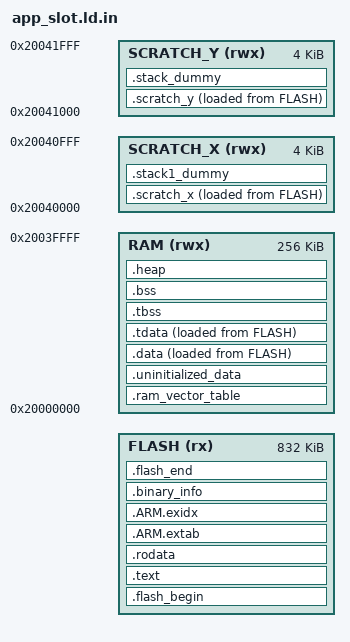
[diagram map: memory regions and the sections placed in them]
/* app_slot.ld.in -- linker script TEMPLATE for a SaftyFW application image
 * meant to run from one of the bootloader's flash slots (docs/BOOTLOADER.md
 * section 2), not from the stock pico-sdk application address.
 *
 * Derived from the vendored pico-sdk's own default app linker script:
 *   $PICO_SDK_PATH/src/rp2_common/pico_crt0/rp2040/memmap_default.ld
 * (pico-sdk 2.x, RP2040 variant -- confirmed present on this machine at
 * C:\pico-tools\pico-sdk). Read that file in full before touching this one;
 * this is a deliberate, commented divergence from it, not an independent
 * design. Everything below that is not called out in a comment is copied
 * from that file unchanged.
 *
 * Two differences from the stock script:
 *
 *   1. No `.boot2` output section, and `.boot2` input sections are
 *      explicitly discarded (see the /DISCARD/ block below). There is
 *      exactly one boot2 in the whole 2MB image -- part of the bootloader's
 *      own build, at flash offset 0 -- and it runs the ROM->boot2->
 *      bootloader handoff once, at power-on. This slot image is entered
 *      directly by the bootloader's jump_to_app() (bootloader/main.c): a
 *      `msr msp` + `bx` straight into this image's own vector table, never
 *      through boot2 again. A second boot2 copy here would be dead weight
 *      (256B) at best; worse, if left as an *unhandled orphan section*
 *      rather than explicitly discarded, GNU ld's orphan-section placement
 *      could tuck it in front of `.vectors` and silently shift the vector
 *      table off the slot's start address, which is exactly the thing
 *      jump_to_app() requires to be there. Discarding it explicitly removes
 *      that hazard rather than hoping the linker's default placement never
 *      changes.
 *
 *      (Why boot2 is a link input here at all, even though we don't want
 *      it: pico-sdk's `pico_standard_link` INTERFACE target links the
 *      `bs2_default_library` into any executable that isn't a `no_flash`
 *      binary type -- see pico_standard_link/CMakeLists.txt -- so it's
 *      present in every ordinary flash-targeted app's link inputs whether
 *      or not the app's own linker script has anywhere to put it.)
 *
 *   2. `FLASH`'s ORIGIN is a build-time placeholder,
 *      `@SAFTYFW_APP_FLASH_ORIGIN@`, substituted by CMake's configure_file()
 *      once per slot (firmware/SaftyFW/CMakeLists.txt's
 *      saftyfw_add_slot_executable() function) -- 0x10011000 for slot A,
 *      0x100E1000 for slot B. `FLASH`'s LENGTH is the hardcoded literal
 *      0xD0000 (832K == BOOTLOADER_SLOT_FLASH_SIZE), NOT computed from
 *      anything -- a linker script cannot #include a C header, so this
 *      value cannot be derived from bootloader/flash_layout.h at build
 *      time. It is a plain copy of that file's
 *      `BOOTLOADER_SLOT_FLASH_SIZE` macro, current as of 2026-08-17.
 *
 *      *** MANUAL SYNC HAZARD ***
 *      If BOOTLOADER_SLOT_FLASH_SIZE ever changes in flash_layout.h, this
 *      LENGTH must be changed here in the same commit, by hand -- nothing
 *      enforces that today. Same for the two ORIGIN values passed in from
 *      CMakeLists.txt (SAFTYFW_APP_SLOT_A_FLASH_ORIGIN /
 *      _B_FLASH_ORIGIN there), which are hand-copied from
 *      BOOTLOADER_SLOT_A_FLASH_OFFSET / _B_FLASH_OFFSET + XIP_BASE. A CI
 *      check that parses flash_layout.h's macros and asserts they match
 *      this file and CMakeLists.txt's literals would close this gap; no
 *      such check exists yet (flagged, not built, this pass).
 *
 * RAM/SCRATCH_X/SCRATCH_Y regions are byte-for-byte identical to the stock
 * script -- SRAM layout does not depend on which flash slot the code runs
 * from.
 */

MEMORY
{
    /* ORIGIN substituted per-slot by configure_file(); LENGTH is
     * BOOTLOADER_SLOT_FLASH_SIZE from bootloader/flash_layout.h, hand-synced
     * (see the MANUAL SYNC HAZARD note above). */
    FLASH(rx) : ORIGIN = @SAFTYFW_APP_FLASH_ORIGIN@, LENGTH = 0xD0000
    RAM(rwx) : ORIGIN =  0x20000000, LENGTH = 256k
    SCRATCH_X(rwx) : ORIGIN = 0x20040000, LENGTH = 4k
    SCRATCH_Y(rwx) : ORIGIN = 0x20041000, LENGTH = 4k
}

ENTRY(_entry_point)

SECTIONS
{
    /* No .boot2 section here -- see header comment. The slot image starts
     * directly with .flash_begin/.text, so KEEP(*(.vectors)) below is the
     * very first thing placed in FLASH, at ORIGIN(FLASH). This is the exact
     * contract bootloader/main.c's jump_to_app() requires: a valid vector
     * table (word 0 = initial SP, word 1 = reset handler) at the slot's
     * start address. */

    .flash_begin : {
        __flash_binary_start = .;
    } > FLASH

    .text : {
        __logical_binary_start = .;
        KEEP (*(.vectors))
        KEEP (*(.binary_info_header))
        __binary_info_header_end = .;
        KEEP (*(.embedded_block))
        __embedded_block_end = .;
        KEEP (*(.reset))
        /* TODO revisit this now memset/memcpy/float in ROM */
        /* bit of a hack right now to exclude all floating point and time critical (e.g. memset, memcpy) code from
         * FLASH ... we will include any thing excluded here in .data below by default */
        *(.init)
        *(EXCLUDE_FILE(*libgcc.a: *libc.a:*lib_a-mem*.o *libm.a:) .text*)
        *(.fini)
        /* Pull all c'tors into .text */
        *crtbegin.o(.ctors)
        *crtbegin?.o(.ctors)
        *(EXCLUDE_FILE(*crtend?.o *crtend.o) .ctors)
        *(SORT(.ctors.*))
        *(.ctors)
        /* Followed by destructors */
        *crtbegin.o(.dtors)
        *crtbegin?.o(.dtors)
        *(EXCLUDE_FILE(*crtend?.o *crtend.o) .dtors)
        *(SORT(.dtors.*))
        *(.dtors)

        . = ALIGN(4);
        /* preinit data */
        PROVIDE_HIDDEN (__preinit_array_start = .);
        KEEP(*(SORT(.preinit_array.*)))
        KEEP(*(.preinit_array))
        PROVIDE_HIDDEN (__preinit_array_end = .);

        . = ALIGN(4);
        /* init data */
        PROVIDE_HIDDEN (__init_array_start = .);
        KEEP(*(SORT(.init_array.*)))
        KEEP(*(.init_array))
        PROVIDE_HIDDEN (__init_array_end = .);

        . = ALIGN(4);
        /* finit data */
        PROVIDE_HIDDEN (__fini_array_start = .);
        *(SORT(.fini_array.*))
        *(.fini_array)
        PROVIDE_HIDDEN (__fini_array_end = .);

        *(.eh_frame*)
        . = ALIGN(4);
    } > FLASH

    .rodata : {
        *(EXCLUDE_FILE(*libgcc.a: *libc.a:*lib_a-mem*.o *libm.a:) .rodata*)
        . = ALIGN(4);
        *(SORT_BY_ALIGNMENT(SORT_BY_NAME(.flashdata*)))
        . = ALIGN(4);
    } > FLASH

    .ARM.extab :
    {
        *(.ARM.extab* .gnu.linkonce.armextab.*)
    } > FLASH

    __exidx_start = .;
    .ARM.exidx :
    {
        *(.ARM.exidx* .gnu.linkonce.armexidx.*)
    } > FLASH
    __exidx_end = .;

    /* Machine inspectable binary information */
    . = ALIGN(4);
    __binary_info_start = .;
    .binary_info :
    {
        KEEP(*(.binary_info.keep.*))
        *(.binary_info.*)
    } > FLASH
    __binary_info_end = .;
    . = ALIGN(4);

    .ram_vector_table (NOLOAD): {
        *(.ram_vector_table)
    } > RAM

    .uninitialized_data (NOLOAD): {
        . = ALIGN(4);
        *(.uninitialized_data*)
    } > RAM

    .data : {
        __data_start__ = .;
        *(vtable)

        *(.time_critical*)

        /* remaining .text and .rodata; i.e. stuff we exclude above because we want it in RAM */
        *(.text*)
        . = ALIGN(4);
        *(.rodata*)
        . = ALIGN(4);

        *(.data*)

        . = ALIGN(4);
        *(.after_data.*)
        . = ALIGN(4);
        /* preinit data */
        PROVIDE_HIDDEN (__mutex_array_start = .);
        KEEP(*(SORT(.mutex_array.*)))
        KEEP(*(.mutex_array))
        PROVIDE_HIDDEN (__mutex_array_end = .);

        . = ALIGN(4);
        *(.jcr)
        . = ALIGN(4);
    } > RAM AT> FLASH

    .tdata : {
        . = ALIGN(4);
        *(.tdata .tdata.* .gnu.linkonce.td.*)
        /* All data end */
        __tdata_end = .;
    } > RAM AT> FLASH
    PROVIDE(__data_end__ = .);

    /* __etext is (for backwards compatibility) the name of the .data init source pointer (...) */
    __etext = LOADADDR(.data);

    .tbss (NOLOAD) : {
        . = ALIGN(4);
        __bss_start__ = .;
        __tls_base = .;
        *(.tbss .tbss.* .gnu.linkonce.tb.*)
        *(.tcommon)

        __tls_end = .;
    } > RAM

    .bss (NOLOAD) : {
        . = ALIGN(4);
        __tbss_end = .;

        *(SORT_BY_ALIGNMENT(SORT_BY_NAME(.bss*)))
        *(COMMON)
        . = ALIGN(4);
        __bss_end__ = .;
    } > RAM

    .heap (NOLOAD):
    {
        __end__ = .;
        end = __end__;
        KEEP(*(.heap*))
    } > RAM
    /* historically on GCC sbrk was growing past __HeapLimit to __StackLimit, however
       to be more compatible, we now set __HeapLimit explicitly to where the end of the heap is */
    __HeapLimit = ORIGIN(RAM) + LENGTH(RAM);

    /* Start and end symbols must be word-aligned */
    .scratch_x : {
        __scratch_x_start__ = .;
        *(.scratch_x.*)
        . = ALIGN(4);
        __scratch_x_end__ = .;
    } > SCRATCH_X AT > FLASH
    __scratch_x_source__ = LOADADDR(.scratch_x);

    .scratch_y : {
        __scratch_y_start__ = .;
        *(.scratch_y.*)
        . = ALIGN(4);
        __scratch_y_end__ = .;
    } > SCRATCH_Y AT > FLASH
    __scratch_y_source__ = LOADADDR(.scratch_y);

    /* .stack*_dummy section doesn't contains any symbols. It is only
     * used for linker to calculate size of stack sections, and assign
     * values to stack symbols later
     *
     * stack1 section may be empty/missing if platform_launch_core1 is not used */

    /* by default we put core 0 stack at the end of scratch Y, so that if core 1
     * stack is not used then all of SCRATCH_X is free.
     */
    .stack1_dummy (NOLOAD):
    {
        *(.stack1*)
    } > SCRATCH_X
    .stack_dummy (NOLOAD):
    {
        KEEP(*(.stack*))
    } > SCRATCH_Y

    .flash_end : {
        KEEP(*(.embedded_end_block*))
        PROVIDE(__flash_binary_end = .);
    } > FLASH

    /* stack limit is poorly named, but historically is maximum heap ptr */
    __StackLimit = ORIGIN(RAM) + LENGTH(RAM);
    __StackOneTop = ORIGIN(SCRATCH_X) + LENGTH(SCRATCH_X);
    __StackTop = ORIGIN(SCRATCH_Y) + LENGTH(SCRATCH_Y);
    __StackOneBottom = __StackOneTop - SIZEOF(.stack1_dummy);
    __StackBottom = __StackTop - SIZEOF(.stack_dummy);
    PROVIDE(__stack = __StackTop);

    /* picolibc and LLVM */
    PROVIDE (__heap_start = __end__);
    PROVIDE (__heap_end = __HeapLimit);
    PROVIDE( __tls_align = MAX(ALIGNOF(.tdata), ALIGNOF(.tbss)) );
    PROVIDE( __tls_size_align = (__tls_size + __tls_align - 1) & ~(__tls_align - 1));
    PROVIDE( __arm32_tls_tcb_offset = MAX(8, __tls_align) );

    /* llvm-libc */
    PROVIDE (_end = __end__);
    PROVIDE (__llvm_libc_heap_limit = __HeapLimit);

    /* Check if data + heap + stack exceeds RAM limit */
    ASSERT(__StackLimit >= __HeapLimit, "region RAM overflowed")

    ASSERT( __binary_info_header_end - __logical_binary_start <= 256, "Binary info must be in first 256 bytes of the binary")

    /* This slot image must fit within the slot -- catch an overrun at link
     * time rather than at flash-write/CRC time. FLASH's LENGTH above is
     * already BOOTLOADER_SLOT_FLASH_SIZE, so this is really just asserting
     * .flash_end landed inside the MEMORY region, which the linker would
     * refuse to do anyway ("region FLASH overflowed") -- this ASSERT gives
     * a clearer message pointing at the actual constraint (the slot, not
     * an arbitrary MEMORY region) if it ever fires.
     */
    ASSERT(__flash_binary_end <= ORIGIN(FLASH) + LENGTH(FLASH),
        "ERROR: application image overflows its BOOTLOADER_SLOT_FLASH_SIZE slot (see flash_layout.h)")

    /* No .boot2 output section on purpose (see header comment) -- discard
     * any .boot2 input section explicitly rather than let the linker's
     * orphan-section placement decide where a leftover 256B blob goes. */
    /DISCARD/ : { *(.boot2) }
}
